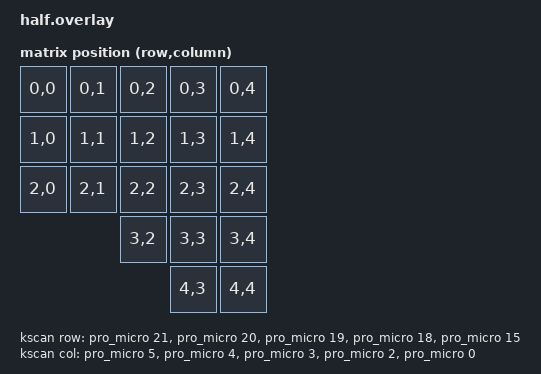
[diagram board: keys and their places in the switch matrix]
// This file was generated from a template. Edit it to match your keyboard.
// See https://zmk.dev/docs/development/hardware-integration/new-shield for more
// instructions.

#include <dt-bindings/zmk/matrix_transform.h>

#include "half-layouts.dtsi"

/ {
    chosen {
        zmk,physical-layout = &default_layout;
    };

    kscan: kscan {
        // If the hardware does not use a switch matrix, change this to the
        // appropriate driver and update the properties below to match.
        // See https://zmk.dev/docs/config/kscan for supported key scan drivers.
        compatible = "zmk,kscan-gpio-matrix";
        // Set this to "col2row" or "row2col" to match the hardware. If using
        // "row2col", change the col-gpios in the _left.overlay and _right.overlay
        // files to (GPIO_ACTIVE_HIGH | GPIO_PULL_DOWN) and the row-gpios here to
        // GPIO_ACTIVE_HIGH.
        diode-direction = "row2col";
        wakeup-source;
        col-gpios = <&pro_micro 5 (GPIO_ACTIVE_HIGH | GPIO_PULL_DOWN)>,
                    <&pro_micro 4 (GPIO_ACTIVE_HIGH | GPIO_PULL_DOWN)>,
                    <&pro_micro 3 (GPIO_ACTIVE_HIGH | GPIO_PULL_DOWN)>,
                    <&pro_micro 2 (GPIO_ACTIVE_HIGH | GPIO_PULL_DOWN)>,
                    <&pro_micro 0 (GPIO_ACTIVE_HIGH | GPIO_PULL_DOWN)>;

        row-gpios = <&pro_micro 21 GPIO_ACTIVE_HIGH>,
                    <&pro_micro 20 GPIO_ACTIVE_HIGH>,
                    <&pro_micro 19 GPIO_ACTIVE_HIGH>,
                    <&pro_micro 18 GPIO_ACTIVE_HIGH>,
                    <&pro_micro 15 GPIO_ACTIVE_HIGH>;
 
        // Replace these comments with the GPIO pins in the matrix.
        // See https://zmk.dev/docs/development/hardware-integration/new-shield#shield-overlays
    };
    default_transform: default_transform {
        compatible = "zmk,matrix-transform";
        columns = <5>;
        rows = <5>;

        // Adjust this mapping if your physical layout isn't full 5x5
        map = <
            RC(0, 0) RC(0, 1) RC(0, 2) RC(0, 3) RC(0, 4)
            RC(1, 0) RC(1, 1) RC(1, 2) RC(1, 3) RC(1, 4)
            RC(2, 0) RC(2, 1) RC(2, 2) RC(2, 3) RC(2, 4)
                              RC(3, 2) RC(3, 3) RC(3, 4)
                                       RC(4, 3) RC(4, 4)
        >;
    };

    };
